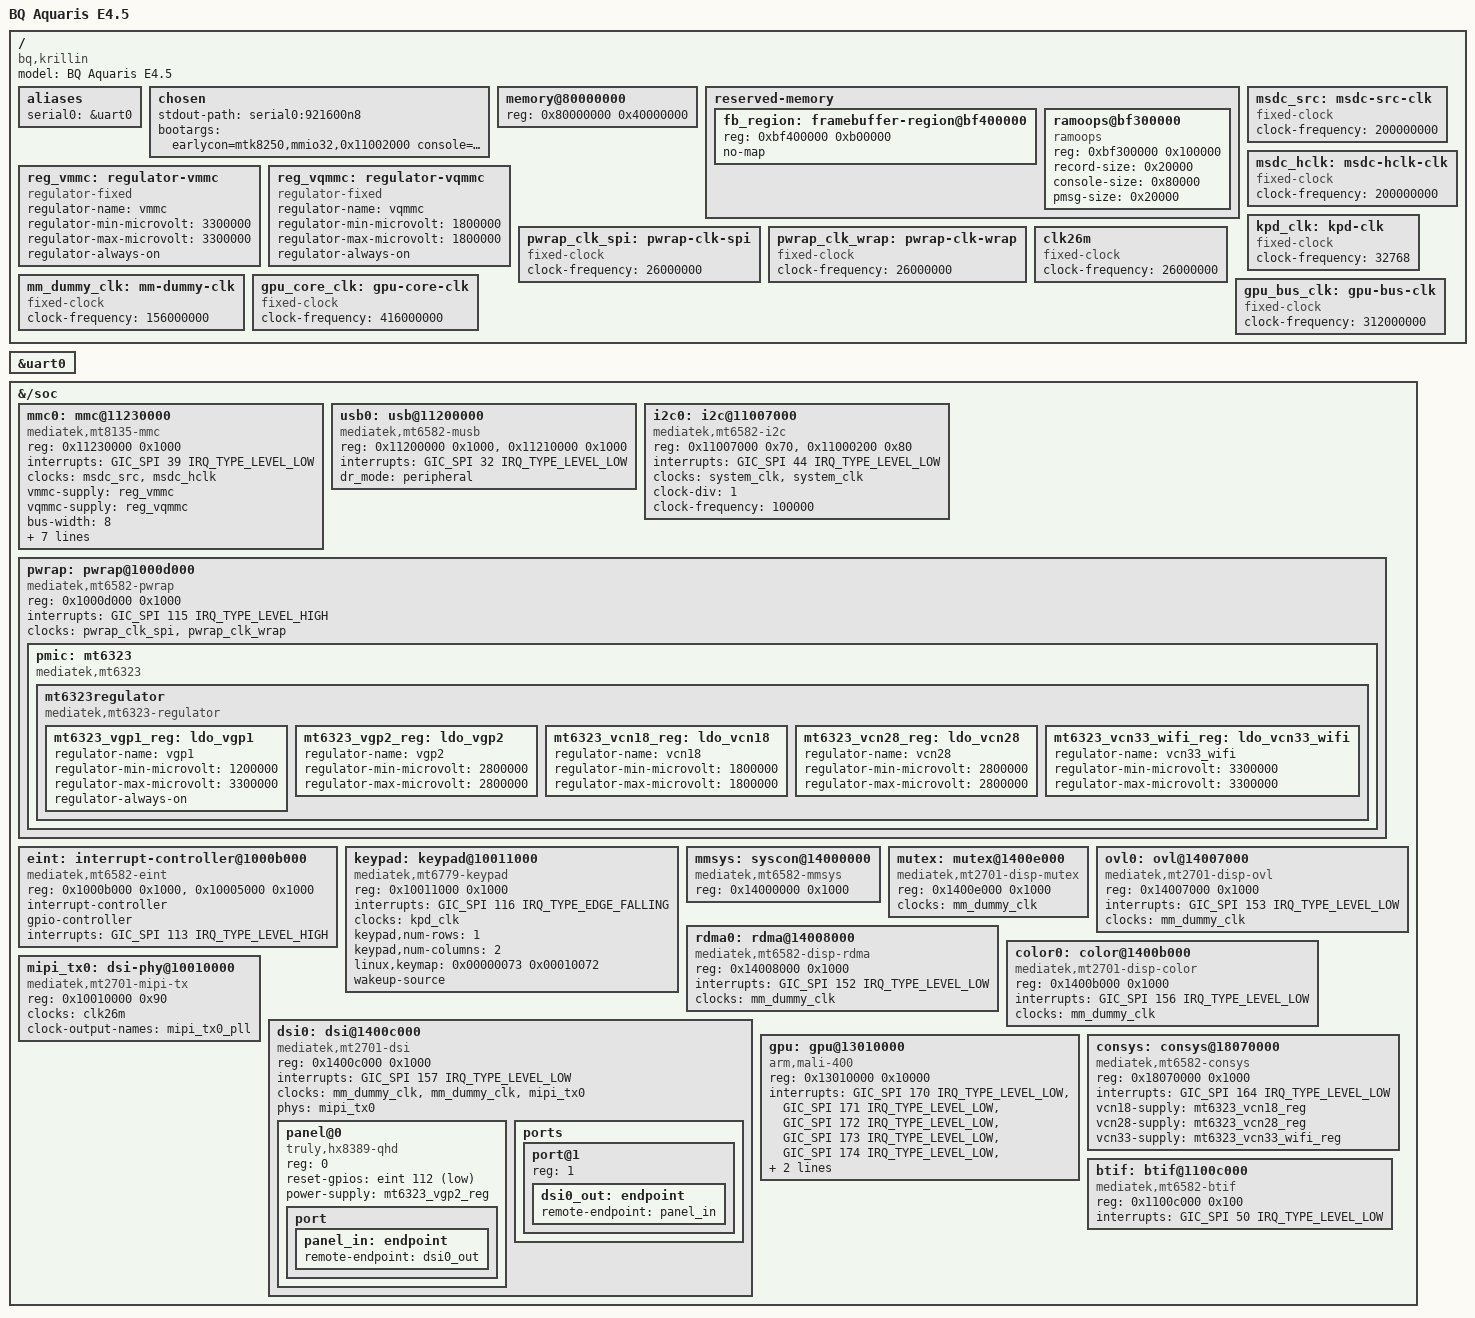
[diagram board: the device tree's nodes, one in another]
// SPDX-License-Identifier: GPL-2.0+
/*
 * BQ Aquaris E4.5 (krillin) — MT6582
 * Primer intento mainline: simple-framebuffer sobre el FB que deja el LK
 * (panel hx8389 qHD DSI modo video, se auto-refresca) + ramoops post-mortem.
 * FB fisico 0xBF400000 (region 12 MB reservada, vista en /proc/iomem del
 * kernel downstream 3.10). stride 2176 = 544*4.
 */

/dts-v1/;
#include <dt-bindings/gpio/gpio.h>
#include "mt6582.dtsi"

/ {
	model = "BQ Aquaris E4.5";
	compatible = "bq,krillin", "mediatek,mt6582";

	aliases {
		serial0 = &uart0;
	};

	chosen {
		stdout-path = "serial0:921600n8";
		#address-cells = <1>;
		#size-cells = <1>;
		ranges;

		bootargs = "earlycon=mtk8250,mmio32,0x11002000 console=ttyS0,921600n8 panic=15 clk_ignore_unused blkdevparts=mmcblk0:512K@512K(ebr1),10240K@9216K(protect_f),10240K@19456K(protect_s),6144K@71168K(sec_ro),1048576K@91136K(android),716800K@1140736K(cache),-@1856512K(usrdata) initcall_debug ignore_loglevel";

		/* FASE 6: simplefb retirado -> mtk_drm es el unico display */
	};

	memory@80000000 {
		device_type = "memory";
		reg = <0x80000000 0x40000000>;
	};

	reserved-memory {
		#address-cells = <1>;
		#size-cells = <1>;
		ranges;

		/* region del framebuffer del LK (mtkfb.0 en downstream) */
		fb_region: framebuffer-region@bf400000 {
			reg = <0xbf400000 0xb00000>;
			no-map;
		};

		/* ultimo MB de la region reservada: logs que sobreviven al reboot */
		ramoops@bf300000 {
			compatible = "ramoops";
			reg = <0xbf300000 0x100000>;
			record-size = <0x20000>;
			console-size = <0x80000>;
			pmsg-size = <0x20000>;
		};
	};
};

&uart0 {
	status = "okay";
};

/ {
	/* relojes fijos para el MSDC: el LK los deja encendidos
	 * (clk_ignore_unused evita que se apaguen) */

	reg_vmmc: regulator-vmmc {
		compatible = "regulator-fixed";
		regulator-name = "vmmc";
		regulator-min-microvolt = <3300000>;
		regulator-max-microvolt = <3300000>;
		regulator-always-on;
	};

	reg_vqmmc: regulator-vqmmc {
		compatible = "regulator-fixed";
		regulator-name = "vqmmc";
		regulator-min-microvolt = <1800000>;
		regulator-max-microvolt = <1800000>;
		regulator-always-on;
	};

	msdc_src: msdc-src-clk {
		compatible = "fixed-clock";
		#clock-cells = <0>;
		clock-frequency = <200000000>;
	};
	msdc_hclk: msdc-hclk-clk {
		compatible = "fixed-clock";
		#clock-cells = <0>;
		clock-frequency = <200000000>;
	};
};

&{/soc} {
	mmc0: mmc@11230000 {
		compatible = "mediatek,mt8135-mmc";
		reg = <0x11230000 0x1000>;
		interrupts = <GIC_SPI 39 IRQ_TYPE_LEVEL_LOW>;
		clocks = <&msdc_src>, <&msdc_hclk>;
		clock-names = "source", "hclk";
		vmmc-supply = <&reg_vmmc>;
		vqmmc-supply = <&reg_vqmmc>;
		bus-width = <8>;
		max-frequency = <12000000>;
		non-removable;
		cap-mmc-highspeed;
		no-mmc-hs400;
		no-mmc-hs200;
		no-sd;
		no-sdio;
		status = "okay";
	};
};

/* M2b: USB MUSB en modo gadget (peripheral). MAC 0x11200000 + SIF 0x11210000.
 * IRQ GIC_SPI 32 (downstream: GIC_PRIVATE_SIGNALS+32 = hwirq 64). Polaridad
 * LEVEL_LOW como el mmc que ya funciona. Clocks/PHY los gestiona el driver. */
&{/soc} {
	usb0: usb@11200000 {
		compatible = "mediatek,mt6582-musb";
		reg = <0x11200000 0x1000>, <0x11210000 0x1000>;
		reg-names = "mac", "sif";
		interrupts = <GIC_SPI 32 IRQ_TYPE_LEVEL_LOW>;
		interrupt-names = "mc";
		dr_mode = "peripheral";
		status = "okay";
	};
};

&{/soc} {
	i2c0: i2c@11007000 {
		compatible = "mediatek,mt6582-i2c";
		reg = <0x11007000 0x70>, <0x11000200 0x80>;
		interrupts = <GIC_SPI 44 IRQ_TYPE_LEVEL_LOW>;
		clocks = <&system_clk>, <&system_clk>;
		clock-names = "main", "dma";
		clock-div = <1>;
		clock-frequency = <100000>;
		#address-cells = <1>;
		#size-cells = <0>;
		status = "okay";
	};
};

/ {
	pwrap_clk_spi: pwrap-clk-spi { compatible = "fixed-clock"; #clock-cells = <0>; clock-frequency = <26000000>; };
	pwrap_clk_wrap: pwrap-clk-wrap { compatible = "fixed-clock"; #clock-cells = <0>; clock-frequency = <26000000>; };
};

&{/soc} {
	pwrap: pwrap@1000d000 {
		compatible = "mediatek,mt6582-pwrap";   /* offsets WACS2 0x9c/a0/a4 coinciden; el LK ya inicializo -> driver salta init */
		reg = <0x1000d000 0x1000>;
		reg-names = "pwrap";
		interrupts = <GIC_SPI 115 IRQ_TYPE_LEVEL_HIGH>;   /* downstream MT6582_PMIC_WRAP_IRQ_ID = GIC_PRIVATE_SIGNALS+115 */
		clocks = <&pwrap_clk_spi>, <&pwrap_clk_wrap>;
		clock-names = "spi", "wrap";
		status = "okay";

		pmic: mt6323 {
			compatible = "mediatek,mt6323";
			mt6323regulator: mt6323regulator {
				compatible = "mediatek,mt6323-regulator";
				mt6323_vgp1_reg: ldo_vgp1 {
					regulator-name = "vgp1";
					regulator-min-microvolt = <1200000>;
					regulator-max-microvolt = <3300000>;
					regulator-always-on;   /* alimenta el tactil; always-on para no perderlo */
				};
			};
		};
	};
};

/* ---- EINT (interrupciones externas) MT6582 — driver gpio-mt6582-eint ---- */
&{/soc} {
	eint: interrupt-controller@1000b000 {
		compatible = "mediatek,mt6582-eint";
		reg = <0x1000b000 0x1000>,	/* [0] EINT */
		      <0x10005000 0x1000>;	/* [1] GPIO */
		interrupt-controller;
		#interrupt-cells = <2>;
		gpio-controller;
		#gpio-cells = <2>;
		interrupts = <GIC_SPI 113 IRQ_TYPE_LEVEL_HIGH>;
	};
};

/* ---- Keypad MT6582 (matriz): VOLUMEN up/down ----
 * KPD @0x10011000 (0xF0011000 virt - 0xE0000000), IRQ GIC_SPI 116 EDGE
 * (downstream MT_KP_IRQ_ID = 32+116). Offsets == mt6779-keypad. */
/ {
	kpd_clk: kpd-clk {
		compatible = "fixed-clock";
		#clock-cells = <0>;
		clock-frequency = <32768>;
	};
};

&{/soc} {
	keypad: keypad@10011000 {
		compatible = "mediatek,mt6779-keypad";
		reg = <0x10011000 0x1000>;
		interrupts = <GIC_SPI 116 IRQ_TYPE_EDGE_FALLING>;
		clocks = <&kpd_clk>;
		clock-names = "kpd";
		keypad,num-rows = <1>;
		keypad,num-columns = <2>;
		/* vol up = indice 0, vol down = indice 1 (downstream cust_kpd.h) */
		linux,keymap = <0x00000073   /* MATRIX_KEY(0,0,KEY_VOLUMEUP=115) */
				0x00010072>; /* MATRIX_KEY(0,1,KEY_VOLUMEDOWN=114) */
		wakeup-source;
		status = "okay";
	};
};

/* ============ DISP DRM — FASE 1: mmsys + MUTEX + fixed-clock ============
 * Primer paso del port mtk_drm (roadmap wf_b890ed35). Levanta el master
 * mmsys (su probe hace platform_device_register_data("mediatek-drm")) y el
 * MUTEX (mediatek,mt2701-disp-mutex; sincroniza el commit con el SOF -> sera
 * lo que de el backlight latcheado). simplefb + mt6582-dispfix SIGUEN ACTIVOS:
 * el DRM aun NO pinta (faltan OVL/RDMA/COLOR/DSI) -> solo validamos que
 * mediatek-drm sondea y el component framework arranca, SIN romper la imagen.
 * IRQ DISP (X_DEFINE_IRQ downstream, SPI=raw-32): MUTEX=161, OVL=153, RDMA=152,
 * COLOR=156, BLS=155, DSI=157 (todos LEVEL_LOW). */
/ {
	mm_dummy_clk: mm-dummy-clk {
		compatible = "fixed-clock";
		#clock-cells = <0>;
		clock-frequency = <156000000>;
	};
};

&{/soc} {
	mmsys: syscon@14000000 {
		compatible = "mediatek,mt6582-mmsys", "syscon";
		reg = <0x14000000 0x1000>;
		#clock-cells = <1>;
		/* sin clocks (los deja LK + clk_ignore_unused), sin power-domains
		 * (no hay scpsys). El driver se anade en of_match_mtk_mmsys[]. */
	};

	mutex: mutex@1400e000 {
		compatible = "mediatek,mt2701-disp-mutex";
		reg = <0x1400e000 0x1000>;
		clocks = <&mm_dummy_clk>;   /* mt2701 pide 1 clk (no_clk=false) -> stub */
	};
};

/* ============ DISP DRM — FASE 2: pipeline OVL -> RDMA -> COLOR ============
 * Hijos de /soc: el mediatek-drm los enumera iterando /soc por compatible
 * (mtk_drm_of_get_ddp_comp_type), NO usa grafo ports. main_path mt2701 =
 * OVL0->RDMA0->COLOR0->BLS->DSI0; aqui los 3 primeros (BLS+DSI = Fase 3, sin
 * ellos el mediatek-drm aun no bindea pero los componentes SI sondean).
 * IRQ (SPI=raw-32, LEVEL_LOW): OVL=153, RDMA=152, COLOR=156. */
&{/soc} {
	ovl0: ovl@14007000 {
		compatible = "mediatek,mt2701-disp-ovl";
		reg = <0x14007000 0x1000>;
		interrupts = <GIC_SPI 153 IRQ_TYPE_LEVEL_LOW>;
		clocks = <&mm_dummy_clk>;
		/* SIN iommus/larb: lee fisico directo, como el dispfix */
	};

	rdma0: rdma@14008000 {
		compatible = "mediatek,mt6582-disp-rdma";   /* variante: MEM_START_ADDR @0x28 */
		reg = <0x14008000 0x1000>;
		interrupts = <GIC_SPI 152 IRQ_TYPE_LEVEL_LOW>;
		clocks = <&mm_dummy_clk>;
	};

	color0: color@1400b000 {
		compatible = "mediatek,mt2701-disp-color";
		reg = <0x1400b000 0x1000>;
		interrupts = <GIC_SPI 156 IRQ_TYPE_LEVEL_LOW>;
		clocks = <&mm_dummy_clk>;
	};
};

/* ============ DISP DRM — FASE 3: DSI + PHY mipi-tx + panel HX8389 ============ */
/ {
	clk26m: clk26m {
		compatible = "fixed-clock";
		#clock-cells = <0>;
		clock-frequency = <26000000>;
	};
};

&{/soc} {
	mipi_tx0: dsi-phy@10010000 {
		compatible = "mediatek,mt2701-mipi-tx";
		reg = <0x10010000 0x90>;
		clocks = <&clk26m>;
		clock-output-names = "mipi_tx0_pll";
		#clock-cells = <0>;
		#phy-cells = <0>;
	};

	dsi0: dsi@1400c000 {
		compatible = "mediatek,mt2701-dsi";
		reg = <0x1400c000 0x1000>;
		interrupts = <GIC_SPI 157 IRQ_TYPE_LEVEL_LOW>;
		clocks = <&mm_dummy_clk>, <&mm_dummy_clk>, <&mipi_tx0>;
		clock-names = "engine", "digital", "hs";
		phys = <&mipi_tx0>;
		phy-names = "dphy";
		#address-cells = <1>;
		#size-cells = <0>;

		panel@0 {
			compatible = "truly,hx8389-qhd";
			reg = <0>;
			reset-gpios = <&eint 112 GPIO_ACTIVE_LOW>;
			power-supply = <&mt6323_vgp2_reg>;
			port {
				panel_in: endpoint { remote-endpoint = <&dsi0_out>; };
			};
		};

		ports {
			#address-cells = <1>;
			#size-cells = <0>;
			port@1 {
				reg = <1>;
				dsi0_out: endpoint { remote-endpoint = <&panel_in>; };
			};
		};
	};
};

&mt6323regulator {
	mt6323_vgp2_reg: ldo_vgp2 {
		regulator-name = "vgp2";
		regulator-min-microvolt = <2800000>;
		regulator-max-microvolt = <2800000>;
	};

	/* WiFi CONSYS: digital 1.8V + analog 2.8V + RF WiFi 3.3V */
	mt6323_vcn18_reg: ldo_vcn18 {
		regulator-name = "vcn18";
		regulator-min-microvolt = <1800000>;
		regulator-max-microvolt = <1800000>;
	};

	mt6323_vcn28_reg: ldo_vcn28 {
		regulator-name = "vcn28";
		regulator-min-microvolt = <2800000>;
		regulator-max-microvolt = <2800000>;
	};

	mt6323_vcn33_wifi_reg: ldo_vcn33_wifi {
		regulator-name = "vcn33_wifi";
		regulator-min-microvolt = <3300000>;
		regulator-max-microvolt = <3300000>;
	};
};

/* ============ lima / Mali-400 MP2 (GPU) ============ */
/ {
	gpu_core_clk: gpu-core-clk { compatible = "fixed-clock"; #clock-cells = <0>; clock-frequency = <416000000>; };
	gpu_bus_clk:  gpu-bus-clk  { compatible = "fixed-clock"; #clock-cells = <0>; clock-frequency = <312000000>; };
};

&{/soc} {
	gpu: gpu@13010000 {
		compatible = "arm,mali-400", "arm,mali-utgard";
		reg = <0x13010000 0x10000>;
		interrupts = <GIC_SPI 170 IRQ_TYPE_LEVEL_LOW>,
			     <GIC_SPI 171 IRQ_TYPE_LEVEL_LOW>,
			     <GIC_SPI 172 IRQ_TYPE_LEVEL_LOW>,
			     <GIC_SPI 173 IRQ_TYPE_LEVEL_LOW>,
			     <GIC_SPI 174 IRQ_TYPE_LEVEL_LOW>,
			     <GIC_SPI 175 IRQ_TYPE_LEVEL_LOW>;
		interrupt-names = "gp", "gpmmu", "pp0", "ppmmu0", "pp1", "ppmmu1";
		clocks = <&gpu_bus_clk>, <&gpu_core_clk>;
		clock-names = "bus", "core";
	};
};

/* ============ WiFi CONSYS MT6582 — M1 bring-up (lee chip-id) ============
 * driver mt6582-consys.c: enciende el CONSYS (reguladores VCN + MTCMOS SPM,
 * mismo patron que el MFG) y lee CONSYS_CHIP_ID (0x18070008) -> debe dar 0x6582.
 * SPM/INFRACFG los mapea el driver por constante; reg aqui = CONN_MCU_CONFIG.
 * IRQ WF_HIF = SPI 164 (downstream WF_HIF_IRQ_ID). */
&{/soc} {
	consys: consys@18070000 {
		compatible = "mediatek,mt6582-consys";
		reg = <0x18070000 0x1000>;
		interrupts = <GIC_SPI 164 IRQ_TYPE_LEVEL_LOW>;
		vcn18-supply = <&mt6323_vcn18_reg>;
		vcn28-supply = <&mt6323_vcn28_reg>;
		vcn33-supply = <&mt6323_vcn33_wifi_reg>;
		status = "okay";
	};
};

/* ============ WiFi M3a — BTIF (transporte serie AP<->CONSYS) ============
 * driver mt6582-btif.c (PIO): canal por el que correra STP/WMT al CONSYS.
 * Base 0x1100C000 (APB), IRQ MT_BTIF = SPI 50. */
&{/soc} {
	btif: btif@1100c000 {
		compatible = "mediatek,mt6582-btif";
		reg = <0x1100c000 0x100>;
		interrupts = <GIC_SPI 50 IRQ_TYPE_LEVEL_LOW>;
		status = "okay";
	};
};
